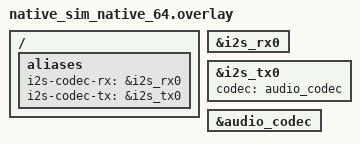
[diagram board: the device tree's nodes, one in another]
/*
 * Copyright 2026 NXP
 *
 * SPDX-License-Identifier: Apache-2.0
 */

/ {
	aliases {
		i2s-codec-rx = &i2s_rx0;
		i2s-codec-tx = &i2s_tx0;
	};
};

&i2s_rx0 {
	status = "okay";
};

&i2s_tx0 {
	status = "okay";
	codec = <&audio_codec>;
};

&audio_codec {
	status = "okay";
};
